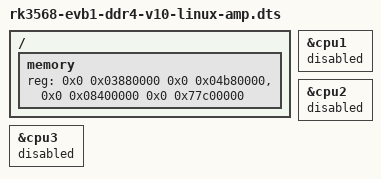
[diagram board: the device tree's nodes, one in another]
// SPDX-License-Identifier: (GPL-2.0+ OR MIT)
/*
 * Copyright (c) 2022 Rockchip Electronics Co., Ltd.
 *
 */

#include "rk3568-evb1-ddr4-v10-linux.dts"
#include "rk3568-amp.dtsi"

/ {
	memory {
		device_type = "memory";
		reg = <0x0 0x03880000 0x0 0x04b80000>,
		      <0x0 0x08400000 0x0 0x77c00000>;
	};
};

&cpu1 {
	status = "disabled";
};

&cpu2 {
	status = "disabled";
};

&cpu3 {
	status = "disabled";
};
